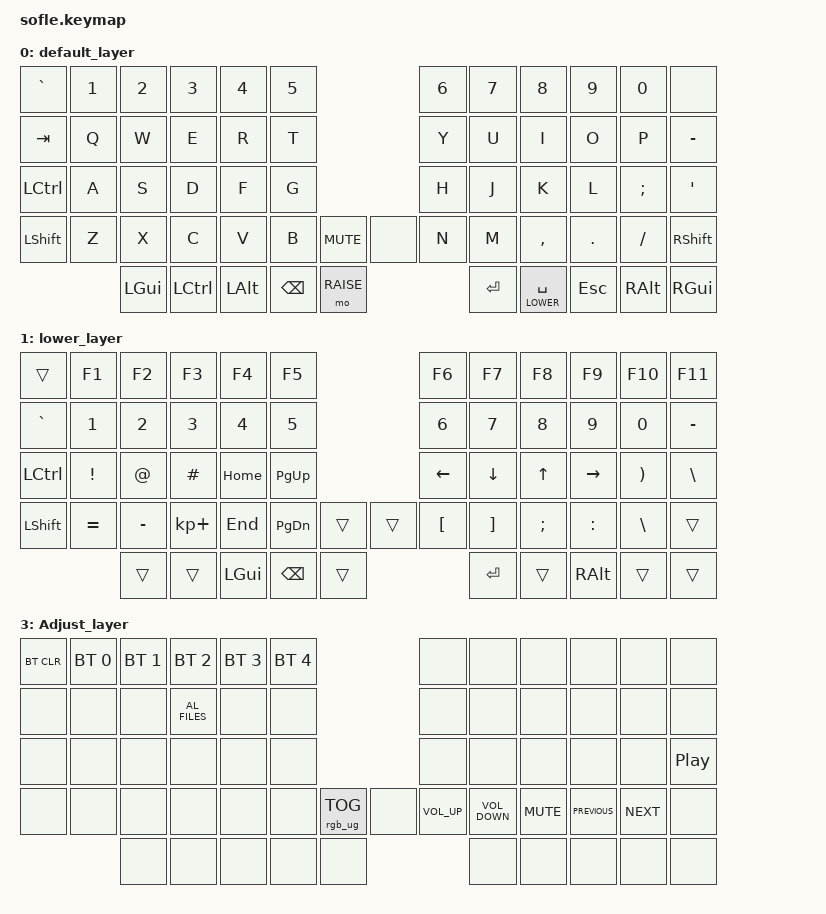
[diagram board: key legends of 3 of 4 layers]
/*
 * Copyright (c) 2020 The ZMK Contributors
 *
 * SPDX-License-Identifier: MIT
*temp
 */

#include <behaviors.dtsi>
#include <dt-bindings/zmk/keys.h>
#include <dt-bindings/zmk/bt.h>
#include <dt-bindings/zmk/rgb.h>
#include <dt-bindings/zmk/ext_power.h>

#define BASE 0
#define LOWER 1
#define RAISE 2
#define ADJUST 3
//test
/ {

   // Activate ADJUST layer by pressing raise and lower
    conditional_layers {
        compatible = "zmk,conditional-layers";
        adjust_layer {
            if-layers = <LOWER RAISE>;
            then-layer = <ADJUST>;
        };
    };

    keymap {
        compatible = "zmk,keymap";

        default_layer {
// ------------------------------------------------------------------------------------------------------------
// |  `    |  1  |  2  |  3   |  4   |  5   |                   |  6   |  7    |  8    |  9   |   0   |       |
// |  ESC  |  Q  |  W  |  E   |  R   |  T   |                   |  Y   |  U    |  I    |  O   |   P   | BKSPC |
// |  TAB  |  A  |  S  |  D   |  F   |  G   |                   |  H   |  J    |  K    |  L   |   ;   |   '   |
// | SHIFT |  Z  |  X  |  C   |  V   |  B   |  MUTE  |  |       |  N   |  M    |  ,    |  .   |   /   | SHIFT |
//               | GUI | ALT  | CTRL | LOWER|  ENTER |  | SPACE | RAISE| CTRL  | ALT   | GUI  |
            bindings = <
&kp GRAVE &kp N1 &kp N2   &kp N3   &kp N4    &kp N5                      &kp N6 &kp N7    &kp N8    &kp N9   &kp N0   &none
&kp TAB   &kp Q  &kp W    &kp E    &kp R     &kp T                       &kp Y  &kp U     &kp I     &kp O    &kp P    &kp MINUS
&kp LCTRL &kp A  &kp S    &kp D    &kp F     &kp G                       &kp H  &kp J     &kp K     &kp L    &kp SEMI &kp SQT
&kp LSHFT &kp Z  &kp X    &kp C    &kp V     &kp B  &kp C_MUTE &none     &kp N  &kp M     &kp COMMA &kp DOT  &kp FSLH &kp RSHFT
                &kp LGUI &kp LCTRL &kp LALT &kp BACKSPACE  &mo RAISE     &kp RET  &lt LOWER SPACE &kp ESC &kp RALT  &kp RGUI
            >;

            sensor-bindings = <&inc_dec_kp C_VOL_UP C_VOL_DN &inc_dec_kp PG_UP PG_DN>;
        };

        lower_layer {
// TODO: Some binds are waiting for shifted keycode support.
// ------------------------------------------------------------------------------------------------------------
// |       |  F1 |  F2 |  F3  |  F4  |  F5  |                   |  F6  |  F7   |  F8   |  F9  |  F10  |  F11  |
// | `     |   1 |   2 |   3  |   4  |   5  |                   |   6  |   7   |   8   |   9  |    0  |  F12  |
// |       |  !  |  @  |  #   |  $   |  %   |                   |  ^   |  &    |  *    |  (   |   )   |   |   |
// |       |  =  |  -  |  +   |  {   |  }   |        |  |       |  [   |  ]    |  ;    |  :   |   \   |       |
//               |     |      |      |      |        |  |       |      |       |       |      |
            bindings = <
&trans    &kp F1    &kp F2    &kp F3      &kp F4    &kp F5                    &kp F6    &kp F7   &kp F8          &kp F9    &kp F10   &kp F11
&kp GRAVE &kp N1    &kp N2    &kp N3      &kp N4    &kp N5                    &kp N6    &kp N7   &kp N8          &kp N9    &kp N0    &kp MINUS
&kp LCTRL    &kp EXCL  &kp AT    &kp HASH    &kp HOME  &kp PG_UP                 &kp LEFT &kp DOWN &kp UP &kp RIGHT  &kp RPAR  &kp BACKSLASH
&kp LSHFT    &kp EQUAL &kp MINUS &kp KP_PLUS &kp END  &kp PG_DN  &trans   &trans &kp LBKT  &kp RBKT &kp SEMI        &kp COLON &kp BSLH  &trans
                    &trans    &trans      &kp LGUI    &kp BACKSPACE    &trans   &kp RET &trans    &kp RALT   &trans          &trans
            >;

            sensor-bindings = <&inc_dec_kp C_VOL_UP C_VOL_DN &inc_dec_kp PG_UP PG_DN>;
        };

        raise_layer {
// ------------------------------------------------------------------------------------------------------------
// |BTCLR| BT1  | BT2  |  BT3  |  BT4  |  BT5 |                |      |      |       |      |       |       |
// |     | INS  | PSCR | GUI   |       |      |                | PGUP |      |   ^   |      |       |       |
// |     | ALT  | CTRL | SHIFT |       | CAPS |                | PGDN |   <- |   v   |  ->  |  DEL  | BKSPC |
// |     | UNDO | CUT  | COPY  | PASTE |      |      |  |      |      |      |       |      |       |       |
//              |      |       |       |      |      |  |      |      |      |       |      |
            bindings = <
&bt BT_CLR &bt BT_SEL 0 &bt BT_SEL 1 &bt BT_SEL 2 &bt BT_SEL 3 &bt BT_SEL 4             &trans    &trans    &trans   &trans    &trans  &trans
&kp GRAVE     &kp F1    &kp F2    &kp F3      &kp F4    &kp F5                    &kp F6    &kp KP_N7    &kp KP_N8  &kp KP_N9    &kp F10   &kp F11
&kp LCTRL     &trans &trans    &kp LBKT     &kp RBKT       &kp CLCK                 &kp MINUS &kp KP_N4  &kp KP_N5 &kp K_LOCK &kp EQUAL &trans  
&kp LSHFT     &trans &trans    &kp LBRC   &kp RBRC  &kp BSLH                       &kp UNDER  &kp KP_N1   &kp KP_N2  &kp KP_N3  &kp FSLH  &kp TILDE
                        &trans       &trans       &kp LGUI     &trans  &kp SPACE   &kp RET  &trans    &kp DOT    &trans   &trans
            >;

            sensor-bindings = <&inc_dec_kp C_VOL_UP C_VOL_DN &inc_dec_kp PG_UP PG_DN>;
        };

// ------------------------------------------------------------------------------------------------------------
// |BTCLR | BT1   | BT2   |  BT3  |  BT4  |  BT5  |                |      |      |       |      |       |       |
// |EXTPWR|RGB_HUD|RGB_HUI|RGB_SAD|RGB_SAI|RGB_EFF|                |      |      |       |      |       |       |
// |      |RGB_BRD|RGB_BRI|       |       |       |                |      |      |       |      |       |       |
// |      |       |       |       |       |       |RGB_TOG| |      |      |      |       |      |       |       |
//                |       |       |       |       |       | |      |      |      |       |      |

        Adjust_layer {
        bindings = <
&bt BT_CLR                      &bt BT_SEL 0    &bt BT_SEL 1    &bt BT_SEL 2    &bt BT_SEL 3    &bt BT_SEL 4                                    &none &none &none &none &none &none
&none &none &none &kp C_AL_FILES &none &none                                                                                                    &none &none &none &none &none &none
&none                           &none &none &none           &none           &none                                           &none &none &none &none &none &kp C_PLAY_PAUSE
&none                           &none           &none           &none           &none           &none                 &rgb_ug RGB_TOG  &none    &kp C_VOLUME_UP &kp C_VOLUME_DOWN &kp C_MUTE &kp C_PREVIOUS &kp C_NEXT &none
                                                &none           &none           &none           &none               &none            &none      &none &none &none &none
        >;
        };

    };
};
